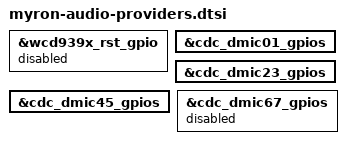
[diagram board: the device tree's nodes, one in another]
// SPDX-License-Identifier: BSD-3-Clause-Clear
/* Copyright (c) Qualcomm Technologies, Inc. and/or its subsidiaries. */

/* Common LPASS hardware providers; board routing stays in Myron's layer. */
#include "lpass-audio-cdc-1.0.dtsi"
#include "lpass-audio-bt-swr.dtsi"
#include "lpass-cdc-gpio.dtsi"
#include "canoe-audio-lpass-reg.dtsi"

&wcd939x_rst_gpio { status = "disabled"; };
&cdc_dmic01_gpios { status = "ok"; };
&cdc_dmic23_gpios { status = "ok"; };
&cdc_dmic45_gpios { status = "ok"; };
&cdc_dmic67_gpios { status = "disabled"; };
